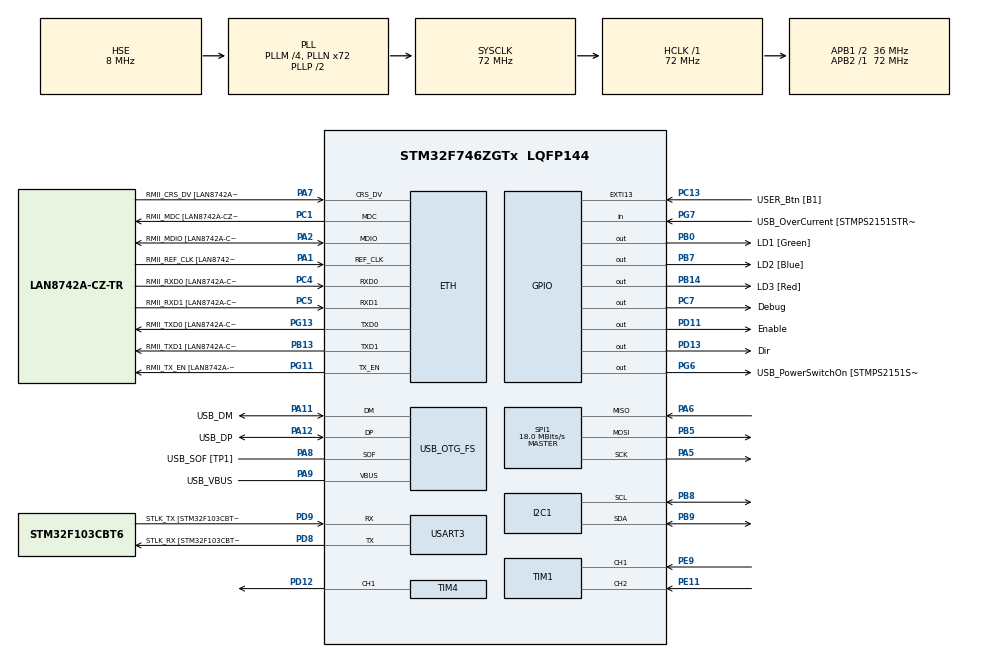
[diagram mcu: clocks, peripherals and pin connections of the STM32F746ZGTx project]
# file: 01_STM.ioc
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ARM.CMSIS.5.7.0.CMSISJjCORE=true
ARM.CMSIS.5.7.0.CMSISJjDSP=Library
CORTEX_M7.CPU_DCache=Disabled
CORTEX_M7.CPU_ICache=Disabled
ETH.MediaInterface=HAL_ETH_RMII_MODE
ETH.PHY_Name=LAN8742A_PHY_ADDRESS
ETH.PHY_Value=0
ETH.PhyAddress=0
ETH.RxMode=ETH_RXPOLLING_MODE
FATFS._MAX_SS=4096
FATFS._MIN_SS=512
FATFS._USE_LFN=1
I2C1.Timing=0x00808CD2
LWIP.BSP.number=1
LWIP.IP_ADDRESS=192.168.113.005
LWIP.LWIP_DHCP=0
LWIP.NETMASK_ADDRESS=255.255.255.000
LWIP.Version=v2.1.2_Cube
LWIP0.BSP.STBoard=false
LWIP0.BSP.api=BSP_COMPONENT_DRIVER
LWIP0.BSP.component=LAN8742
LWIP0.BSP.instance=LAN8742
LWIP0.BSP.name=Driver_PHY
LWIP0.BSP.semaphore=S_LAN8742
LWIP0.BSP.solution=LAN8742
Mcu.Family=STM32F7
Mcu.Name=STM32F746ZGTx
Mcu.Package=LQFP144
NVIC.ETH_IRQn=true\:0\:0\:false\:false\:true\:true\:true\:true
NVIC.ETH_WKUP_IRQn=true\:0\:0\:false\:false\:true\:true\:true\:true
NVIC.EXTI15_10_IRQn=true\:0\:0\:false\:false\:true\:true\:true\:true
NVIC.I2C1_ER_IRQn=true\:0\:0\:false\:false\:true\:true\:true\:true
NVIC.I2C1_EV_IRQn=true\:0\:0\:false\:false\:true\:true\:true\:true
NVIC.PriorityGroup=NVIC_PRIORITYGROUP_4
NVIC.SPI1_IRQn=true\:0\:0\:false\:false\:true\:true\:true\:true
NVIC.TIM1_CC_IRQn=true\:0\:0\:false\:false\:true\:true\:true\:true
NVIC.TIM3_IRQn=true\:0\:0\:false\:false\:true\:true\:true\:true
NVIC.TIM4_IRQn=true\:0\:0\:false\:false\:true\:true\:true\:true
NVIC.TIM5_IRQn=true\:0\:0\:false\:false\:true\:true\:true\:true
NVIC.USART3_IRQn=true\:0\:0\:false\:false\:true\:true\:true\:true
PA1.GPIO_Label=RMII_REF_CLK [LAN8742A-CZ-TR_REFCLK0]
PA1.Mode=RMII
PA1.Signal=ETH_REF_CLK
PA10.GPIO_Label=USB_ID
PA10.Signal=USB_OTG_FS_ID
PA11.GPIO_Label=USB_DM
PA11.Mode=Device_Only
PA11.Signal=USB_OTG_FS_DM
PA12.GPIO_Label=USB_DP
PA12.Mode=Device_Only
PA12.Signal=USB_OTG_FS_DP
PA13.GPIO_Label=TMS
PA13.Mode=Serial_Wire
PA13.Signal=SYS_JTMS-SWDIO
PA14.GPIO_Label=TCK
PA14.Mode=Serial_Wire
PA14.Signal=SYS_JTCK-SWCLK
PA2.GPIO_Label=RMII_MDIO [LAN8742A-CZ-TR_MDIO]
PA2.Mode=RMII
PA2.Signal=ETH_MDIO
PA5.Mode=Full_Duplex_Master
PA5.Signal=SPI1_SCK
PA6.Mode=Full_Duplex_Master
PA6.Signal=SPI1_MISO
PA7.GPIO_Label=RMII_CRS_DV [LAN8742A-CZ-TR_CRS_DV]
PA7.Mode=RMII
PA7.Signal=ETH_CRS_DV
PA8.GPIO_Label=USB_SOF [TP1]
PA8.Mode=Activate_SOF_FS
PA8.Signal=USB_OTG_FS_SOF
PA9.GPIO_Label=USB_VBUS
PA9.Mode=Activate_VBUS
PA9.Signal=USB_OTG_FS_VBUS
PB0.GPIO_Label=LD1 [Green]
PB0.Signal=GPIO_Output
PB13.GPIO_Label=RMII_TXD1 [LAN8742A-CZ-TR_TXD1]
PB13.Mode=RMII
PB13.Signal=ETH_TXD1
PB14.GPIO_Label=LD3 [Red]
PB14.Signal=GPIO_Output
PB3.GPIO_Label=SW0
PB3.Signal=SYS_JTDO-SWO
PB5.Mode=Full_Duplex_Master
PB5.Signal=SPI1_MOSI
PB7.GPIO_Label=LD2 [Blue]
PB7.Signal=GPIO_Output
PB8.Mode=I2C
PB8.Signal=I2C1_SCL
PB9.Mode=I2C
PB9.Signal=I2C1_SDA
PC1.GPIO_Label=RMII_MDC [LAN8742A-CZ-TR_MDC]
PC1.Mode=RMII
PC1.Signal=ETH_MDC
PC13.GPIO_Label=USER_Btn [B1]
PC13.Signal=GPXTI13
PC14/OSC32_IN.Mode=LSE-External-Oscillator
PC14/OSC32_IN.Signal=RCC_OSC32_IN
PC15/OSC32_OUT.Mode=LSE-External-Oscillator
PC15/OSC32_OUT.Signal=RCC_OSC32_OUT
PC4.GPIO_Label=RMII_RXD0 [LAN8742A-CZ-TR_RXD0]
PC4.Mode=RMII
PC4.Signal=ETH_RXD0
PC5.GPIO_Label=RMII_RXD1 [LAN8742A-CZ-TR_RXD1]
PC5.Mode=RMII
PC5.Signal=ETH_RXD1
PC7.GPIO_Label=Debug
PC7.Signal=GPIO_Output
PD11.GPIO_Label=Enable
PD11.Signal=GPIO_Output
PD12.Signal=S_TIM4_CH1
PD13.GPIO_Label=Dir
PD13.Signal=GPIO_Output
PD8.GPIO_Label=STLK_RX [STM32F103CBT6_PA3]
PD8.GPIO_PuPd=GPIO_PULLUP
PD8.Mode=Asynchronous
PD8.Signal=USART3_TX
PD9.GPIO_Label=STLK_TX [STM32F103CBT6_PA2]
PD9.GPIO_PuPd=GPIO_PULLUP
PD9.Mode=Asynchronous
PD9.Signal=USART3_RX
PE11.Signal=S_TIM1_CH2
PE9.Signal=S_TIM1_CH1
PG11.GPIO_Label=RMII_TX_EN [LAN8742A-CZ-TR_TXEN]
PG11.Mode=RMII
PG11.Signal=ETH_TX_EN
PG13.GPIO_Label=RMII_TXD0 [LAN8742A-CZ-TR_TXD0]
PG13.Mode=RMII
PG13.Signal=ETH_TXD0
PG6.GPIO_Label=USB_PowerSwitchOn [STMPS2151STR_EN]
PG6.Signal=GPIO_Output
PG7.GPIO_Label=USB_OverCurrent [STMPS2151STR_FAULT]
PG7.Signal=GPIO_Input
PH0/OSC_IN.GPIO_Label=MCO [STM32F103CBT6_PA8]
PH0/OSC_IN.Mode=HSE-External-Clock-Source
PH0/OSC_IN.Signal=RCC_OSC_IN
PH1/OSC_OUT.Mode=HSE-External-Clock-Source
PH1/OSC_OUT.Signal=RCC_OSC_OUT
ProjectManager.HeapSize=0x200
ProjectManager.StackSize=0x400
ProjectManager.TargetToolchain=STM32CubeIDE
RCC.48MHZClocksFreq_Value=24000000
RCC.AHBFreq_Value=72000000
RCC.APB1CLKDivider=RCC_HCLK_DIV2
RCC.APB1Freq_Value=36000000
RCC.APB1TimFreq_Value=72000000
RCC.APB2Freq_Value=72000000
RCC.APB2TimFreq_Value=72000000
RCC.CortexFreq_Value=72000000
RCC.HCLKFreq_Value=72000000
RCC.HSE_VALUE=8000000
RCC.HSI_VALUE=16000000
RCC.PLLM=4
RCC.PLLMUL=RCC_PLL_MUL9
RCC.PLLN=72
RCC.PLLQ=3
RCC.PRESCALERUSB=RCC_USBCLKSOURCE_PLL_DIV1_5
RCC.SYSCLKFreq_VALUE=72000000
RCC.SYSCLKSource=RCC_SYSCLKSOURCE_PLLCLK
RCC.SYSCLKSourceVirtual=RCC_SYSCLKSOURCE_PLLCLK
RCC.USBFreq_Value=48000000
RCC.VCOOutputFreq_Value=144000000
SH.S_TIM1_CH1.0=TIM1_CH1,Encoder_Interface
SH.S_TIM1_CH2.0=TIM1_CH2,Encoder_Interface
SH.S_TIM4_CH1.0=TIM4_CH1,PWM Generation1 CH1
SPI1.BaudRatePrescaler=SPI_BAUDRATEPRESCALER_4
SPI1.CalculateBaudRate=18.0 MBits/s
SPI1.DataSize=SPI_DATASIZE_8BIT
SPI1.Direction=SPI_DIRECTION_2LINES
SPI1.Mode=SPI_MODE_MASTER
SPI1.VirtualType=VM_MASTER
TIM1.EncoderMode=TIM_ENCODERMODE_TI12
TIM3.Period=9999
TIM3.Prescaler=719
TIM4.Channel-PWM\ Generation1\ CH1=TIM_CHANNEL_1
TIM4.Period=9999
TIM4.Prescaler=7199
TIM4.Pulse-PWM\ Generation1\ CH1=10
TIM5.Period=9999
TIM5.Prescaler=719
USART3.VirtualMode-Asynchronous=VM_ASYNC
USB_OTG_FS.VirtualMode=Device_Only
VP_ARM.CMSIS_VS_CMSISJjCORE_5.4.0_5.7.0.Mode=CMSISJjCORE
VP_ARM.CMSIS_VS_CMSISJjDSP_1.8.0_5.7.0.Mode=CMSISJjDSP
VP_FATFS_VS_Generic.Mode=User_defined
VP_LWIP_VS_Enabled.Mode=Enabled
VP_RTC_VS_RTC_Activate.Mode=RTC_Enabled
VP_RTC_VS_RTC_Calendar.Mode=RTC_Calendar
VP_TIM3_VS_ClockSourceINT.Mode=Internal
VP_TIM4_VS_ClockSourceINT.Mode=Internal
VP_TIM5_VS_ClockSourceINT.Mode=Internal
board=NUCLEO-F746ZG

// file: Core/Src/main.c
/* USER CODE BEGIN Header */
/**
 ******************************************************************************
 * @file           : main.c
 * @brief          : Main program body
 ******************************************************************************
 * @attention
 *
 * Copyright (c) 2024 STMicroelectronics.
 * All rights reserved.
 *
 * This software is licensed under terms that can be found in the LICENSE file
 * in the root directory of this software component.
 * If no LICENSE file comes with this software, it is provided AS-IS.
 *
 ******************************************************************************
 */
/* USER CODE END Header */
#include "main.h"
#include "fatfs.h"
#include "i2c.h"
#include "lwip.h"
#include "rtc.h"
#include "spi.h"
#include "tim.h"
#include "usart.h"
#include "usb_otg.h"
#include "gpio.h"

/* USER CODE BEGIN Includes */
#include <stdio.h>
#include <string.h>
#include "interrupts.h"
#include "fatfs_sd.h"
#include "miscellaneous.h"
/* USER CODE END Includes */

/* USER CODE BEGIN PV */
extern _PULSER_handle hpsr;
/* USER CODE END PV */

void SystemClock_Config(void);

int main(void)
{

  /* MCU Configuration--------------------------------------------------------*/

  /* Reset of all peripherals, Initializes the Flash interface and the Systick. */
  HAL_Init();

  /* Configure the system clock */
  SystemClock_Config();

  /* Initialize all configured peripherals */
  MX_GPIO_Init();
  MX_USART3_UART_Init();
  MX_USB_OTG_FS_PCD_Init();
  MX_I2C1_Init();
  MX_SPI1_Init();
  MX_FATFS_Init();
  MX_TIM4_Init();
  MX_TIM1_Init();
  MX_TIM3_Init();
  MX_LWIP_Init();
  MX_TIM5_Init();
  MX_RTC_Init();
  /* USER CODE BEGIN 2 */
  LCD_Init(&hi2c1);
  UDP_Init();
  init_peripherals();
  /* USER CODE END 2 */

  /* Infinite loop */
  /* USER CODE BEGIN WHILE */
  while (1)
  {
	  MX_LWIP_Process();
    /* USER CODE END WHILE */

  }
}

void SystemClock_Config(void)
{
  RCC_OscInitTypeDef RCC_OscInitStruct = {0};
  RCC_ClkInitTypeDef RCC_ClkInitStruct = {0};

  /** Configure LSE Drive Capability
  */
  HAL_PWR_EnableBkUpAccess();

  /** Configure the main internal regulator output voltage
  */
  __HAL_RCC_PWR_CLK_ENABLE();
  __HAL_PWR_VOLTAGESCALING_CONFIG(PWR_REGULATOR_VOLTAGE_SCALE3);

  /** Initializes the RCC Oscillators according to the specified parameters
  * in the RCC_OscInitTypeDef structure.
  */
  RCC_OscInitStruct.OscillatorType = RCC_OSCILLATORTYPE_LSI|RCC_OSCILLATORTYPE_HSE;
  RCC_OscInitStruct.HSEState = RCC_HSE_BYPASS;
  RCC_OscInitStruct.LSIState = RCC_LSI_ON;
  RCC_OscInitStruct.PLL.PLLState = RCC_PLL_ON;
  RCC_OscInitStruct.PLL.PLLSource = RCC_PLLSOURCE_HSE;
  RCC_OscInitStruct.PLL.PLLM = 4;
  RCC_OscInitStruct.PLL.PLLN = 72;
  RCC_OscInitStruct.PLL.PLLP = RCC_PLLP_DIV2;
  RCC_OscInitStruct.PLL.PLLQ = 3;
  if (HAL_RCC_OscConfig(&RCC_OscInitStruct) != HAL_OK)
  {
    Error_Handler();
  }

  /** Initializes the CPU, AHB and APB buses clocks
  */
  RCC_ClkInitStruct.ClockType = RCC_CLOCKTYPE_HCLK|RCC_CLOCKTYPE_SYSCLK
                              |RCC_CLOCKTYPE_PCLK1|RCC_CLOCKTYPE_PCLK2;
  RCC_ClkInitStruct.SYSCLKSource = RCC_SYSCLKSOURCE_PLLCLK;
  RCC_ClkInitStruct.AHBCLKDivider = RCC_SYSCLK_DIV1;
  RCC_ClkInitStruct.APB1CLKDivider = RCC_HCLK_DIV2;
  RCC_ClkInitStruct.APB2CLKDivider = RCC_HCLK_DIV1;

  if (HAL_RCC_ClockConfig(&RCC_ClkInitStruct, FLASH_LATENCY_2) != HAL_OK)
  {
    Error_Handler();
  }
}

void Error_Handler(void)
{
  __disable_irq();
  while (1)
  {
  }
}
